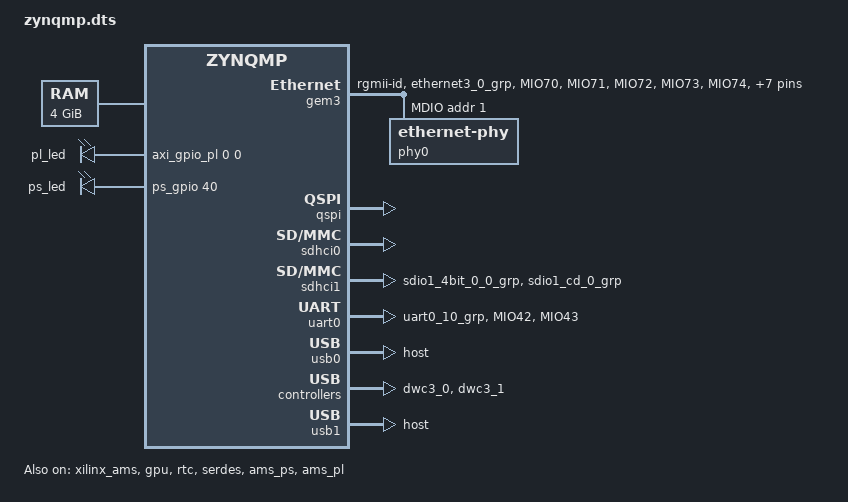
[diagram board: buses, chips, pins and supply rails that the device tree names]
/*
 * CAUTION: This file is automatically generated by Xilinx.
 * Version:  
 * Today is: Tue Apr  7 18:16:07 2026
 */


/dts-v1/;
#include "zynqmp.dtsi"
#include "zynqmp-clk-ccf.dtsi"
#include "pl.dtsi"
#include "pcw.dtsi"
/ {
	chosen {
		bootargs = "earlycon clk_ignore_unused";
		stdout-path = "serial0:115200n8";
	};
	aliases {
		ethernet0 = &gem3;
		serial0 = &uart0;
		spi0 = &qspi;
	};
	memory {
		device_type = "memory";
		reg = <0x0 0x0 0x0 0x7ff00000>, <0x00000008 0x00000000 0x0 0x80000000>;
	};
};
/*
 * CAUTION: This file is automatically generated by Xilinx.
 * Version:  
 * Today is: Tue Apr  7 18:16:07 2026
 */


&gem3 {
	local-mac-address = [00 0a 35 00 00 00];
};
/*
 * CAUTION: This file is automatically generated by Xilinx.
 * Version:  
 * Today is: Tue Apr  7 18:16:07 2026
 */


&gic {
	num_cpus = <2>;
	num_interrupts = <96>;
};
&lpd_dma_chan1 {
	status = "okay";
};
&lpd_dma_chan2 {
	status = "okay";
};
&lpd_dma_chan3 {
	status = "okay";
};
&lpd_dma_chan4 {
	status = "okay";
};
&lpd_dma_chan5 {
	status = "okay";
};
&lpd_dma_chan6 {
	status = "okay";
};
&lpd_dma_chan7 {
	status = "okay";
};
&lpd_dma_chan8 {
	status = "okay";
};
&xilinx_ams {
	status = "okay";
};
&gem3 {
	phy-mode = "rgmii-id";
	status = "okay";
	xlnx,ptp-enet-clock = <0x0>;
};
&fpd_dma_chan1 {
	status = "okay";
};
&fpd_dma_chan2 {
	status = "okay";
};
&fpd_dma_chan3 {
	status = "okay";
};
&fpd_dma_chan4 {
	status = "okay";
};
&fpd_dma_chan5 {
	status = "okay";
};
&fpd_dma_chan6 {
	status = "okay";
};
&fpd_dma_chan7 {
	status = "okay";
};
&fpd_dma_chan8 {
	status = "okay";
};
&gpio {
	emio-gpio-width = <32>;
	gpio-mask-high = <0x0>;
	gpio-mask-low = <0x5600>;
	status = "okay";
};
&gpu {
	status = "okay";
	xlnx,tz-nonsecure = <0x1>;
};
&qspi {
	is-dual = <0>;
	num-cs = <1>;
	spi-rx-bus-width = <2>;
	spi-tx-bus-width = <2>;
	status = "okay";
};
&rtc {
	status = "okay";
};
&sdhci0 {
	clock-frequency = <187498123>;
	status = "okay";
	xlnx,mio_bank = <0x0>;
};
&sdhci1 {
	clock-frequency = <187498123>;
	status = "okay";
	xlnx,mio_bank = <0x1>;
};
&serdes {
	status = "okay";
};
&uart0 {
	cts-override ;
	device_type = "serial";
	port-number = <0>;
	status = "okay";
	u-boot,dm-pre-reloc ;
};
&usb0 {
	status = "okay";
	xlnx,tz-nonsecure = <0x1>;
	xlnx,usb-polarity = <0x0>;
	xlnx,usb-reset-io = <0x1f>;
	xlnx,usb-reset-mode = <0x1>;
};
&dwc3_0 {
	status = "okay";
};
&ams_ps {
	status = "okay";
};
&ams_pl {
	status = "okay";
};
/*
 * CAUTION: This file is automatically generated by Xilinx.
 * Version:  
 * Today is: Tue Apr  7 18:16:07 2026
 */


/ {
	amba_pl: amba_pl@0 {
		#address-cells = <2>;
		#size-cells = <2>;
		compatible = "simple-bus";
		ranges ;
		axi_dma_0: dma@80001000 {
			#dma-cells = <1>;
			clock-names = "s_axi_lite_aclk", "m_axi_sg_aclk", "m_axi_mm2s_aclk", "m_axi_s2mm_aclk";
			clocks = <&zynqmp_clk 71>, <&zynqmp_clk 71>, <&zynqmp_clk 71>, <&zynqmp_clk 71>;
			compatible = "xlnx,axi-dma-7.1", "xlnx,axi-dma-1.00.a";
			interrupt-names = "mm2s_introut", "s2mm_introut";
			interrupt-parent = <&gic>;
			interrupts = <0 89 4 0 90 4>;
			reg = <0x0 0x80001000 0x0 0x1000>;
			xlnx,addrwidth = <0x40>;
			xlnx,include-sg ;
			xlnx,sg-length-width = <0x1a>;
			dma-channel@80001000 {
				compatible = "xlnx,axi-dma-mm2s-channel";
				dma-channels = <0x1>;
				interrupts = <0 89 4>;
				xlnx,datawidth = <0x80>;
				xlnx,device-id = <0x0>;
			};
			dma-channel@80001030 {
				compatible = "xlnx,axi-dma-s2mm-channel";
				dma-channels = <0x1>;
				interrupts = <0 90 4>;
				xlnx,datawidth = <0x20>;
				xlnx,device-id = <0x0>;
			};
		};
		axi_gpio_0: gpio@80000000 {
			#gpio-cells = <3>;
			clock-names = "s_axi_aclk";
			clocks = <&zynqmp_clk 71>;
			compatible = "xlnx,axi-gpio-2.0", "xlnx,xps-gpio-1.00.a";
			gpio-controller ;
			reg = <0x0 0x80000000 0x0 0x1000>;
			xlnx,all-inputs = <0x0>;
			xlnx,all-inputs-2 = <0x0>;
			xlnx,all-outputs = <0x1>;
			xlnx,all-outputs-2 = <0x0>;
			xlnx,dout-default = <0x00000000>;
			xlnx,dout-default-2 = <0x00000000>;
			xlnx,gpio-width = <0x1>;
			xlnx,gpio2-width = <0x20>;
			xlnx,interrupt-present = <0x0>;
			xlnx,is-dual = <0x0>;
			xlnx,tri-default = <0xFFFFFFFF>;
			xlnx,tri-default-2 = <0xFFFFFFFF>;
		};
	};
};
#include <dt-bindings/pinctrl/pinctrl-zynqmp.h>

&gem3 {
	pinctrl-names = "default";
	pinctrl-0 = <&pinctrl_gem3_default>;

	mdio: mdio {
		#address-cells = <1>;
		#size-cells = <0>;
		phy0: ethernet-phy@1 {
			reg = <0x1>;
			device_type = "ethernet-phy";
		};
	};
};

&sdhci1 {
	disable-wp;
	no-1-8-v;
	u-boot,dm-pre-reloc;
	pinctrl-names = "default";
	pinctrl-0 = <&pinctrl_sdhci1_default>;
};

&uart0 {
	pinctrl-names = "default";
	pinctrl-0 = <&pinctrl_uart0_default>;
};

&usb0 {
    status  = "okay";
    dr_mode = "host";
};
&dwc3_0 {
    status = "okay";
};

&usb1 {
    status  = "okay";
    dr_mode = "host";
};
&dwc3_1 {
    status = "okay";
};

&pinctrl0 {
	status = "okay";
	u-boot,dm-pre-reloc;

	pinctrl_gem3_default: gem3-default{
		mux {
			function = "ethernet3";
			groups = "ethernet3_0_grp";
		};

		conf {
			groups = "ethernet3_0_grp";
			slew-rate = <SLEW_RATE_SLOW>;
			io-standard = <IO_STANDARD_LVCMOS18>;
		};
		
		conf-rx {
			pins = "MIO70", "MIO71", "MIO72", "MIO73", "MIO74", "MIO75";
			bias-high-impedance;
			low-power-disable;
		};

		conf-tx {
			pins = "MIO64", "MIO65", "MIO66", "MIO67", "MIO68", "MIO69";
			bias-disable;
			low-power-enable;
		};
	};

	pinctrl_uart0_default: uart0-default {
		mux {
			groups = "uart0_10_grp";
			function = "uart0";
		};

		conf {
			groups = "uart0_10_grp";
			slew-rate = <SLEW_RATE_SLOW>;
			io-standard = <IO_STANDARD_LVCMOS18>;
		};

		conf-rx {
			pins = "MIO42";
			bias-high-impedance;
		};

		conf-tx {
			pins = "MIO43";
			bias-disable;
		};
	};

	pinctrl_sdhci1_default: sdhci1-default {
		mux {
			groups = "sdio1_4bit_0_0_grp";
			function = "sdio1";
		};

		conf {
			groups = "sdio1_4bit_0_0_grp";
			slew-rate = <SLEW_RATE_SLOW>;
			power-source = <IO_STANDARD_LVCMOS18>;
			bias-disable;
		};

		mux-cd {
			groups = "sdio1_cd_0_grp";
			function = "sdio1_cd";
		};

		conf-cd {
			groups = "sdio1_cd_0_grp";
			bias-high-impedance;
			bias-pull-up;
			slew-rate = <SLEW_RATE_SLOW>;
			power-source = <IO_STANDARD_LVCMOS18>;
		};
	};
};

&axi_dma_0 {
    dma-coherent;
};

&amba_pl {

	dma_proxy {  
		compatible ="xlnx,dma_proxy";
		dmas = <&axi_dma_0 0  &axi_dma_0 1>;
		dma-names = "dma_proxy_tx", "dma_proxy_rx";  
		dma-coherent;
	};

	leds {
		compatible = "gpio-leds";

		pl-led {
			label = "pl_led";
			gpios = <&axi_gpio_pl 0 0 0>;
			default-state = "on";
			linux,default-trigger = "none";
		};

		ps-led{
			label = "ps_led";
			gpios = <&ps_gpio 40 0>;
			default-state = "on";
			linux,default-trigger = "none";
		};
    };
};

&axi_gpio_0{
	label = "axi_gpio_pl";
}
